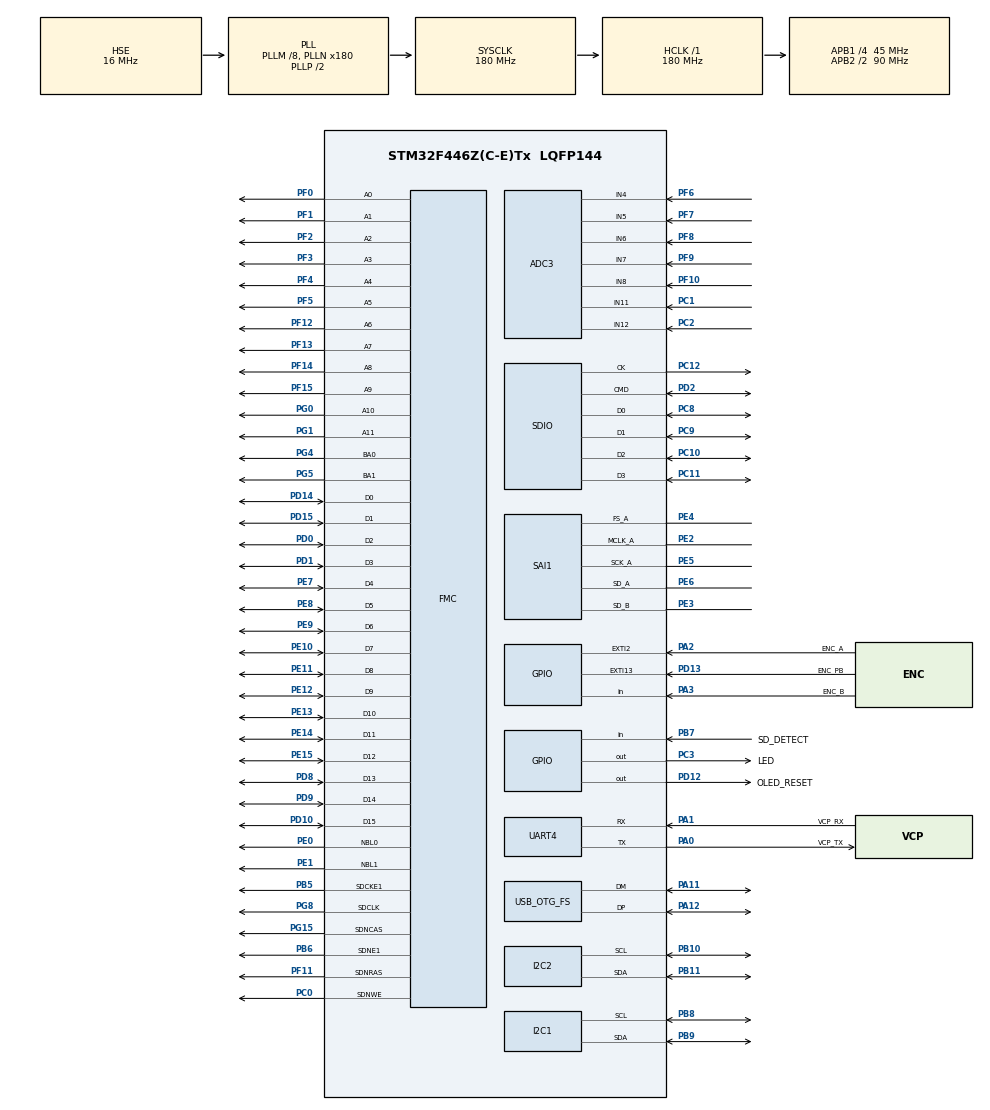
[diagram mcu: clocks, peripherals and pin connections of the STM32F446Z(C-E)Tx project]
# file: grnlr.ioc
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ADC3.Channel-0\#ChannelRegularConversion=ADC_CHANNEL_4
ADC3.NbrOfConversionFlag=1
ADC3.Rank-0\#ChannelRegularConversion=1
ADC3.SamplingTime-0\#ChannelRegularConversion=ADC_SAMPLETIME_3CYCLES
Dma.I2C2_TX.4.Direction=DMA_MEMORY_TO_PERIPH
Dma.I2C2_TX.4.FIFOMode=DMA_FIFOMODE_DISABLE
Dma.I2C2_TX.4.Instance=DMA1_Stream7
Dma.I2C2_TX.4.MemDataAlignment=DMA_MDATAALIGN_BYTE
Dma.I2C2_TX.4.MemInc=DMA_MINC_ENABLE
Dma.I2C2_TX.4.Mode=DMA_NORMAL
Dma.I2C2_TX.4.PeriphDataAlignment=DMA_PDATAALIGN_BYTE
Dma.I2C2_TX.4.PeriphInc=DMA_PINC_DISABLE
Dma.I2C2_TX.4.Priority=DMA_PRIORITY_MEDIUM
Dma.Request0=SAI1_A
Dma.Request1=SAI1_B
Dma.Request2=SDIO_RX
Dma.Request3=SDIO_TX
Dma.Request4=I2C2_TX
Dma.SAI1_A.0.Direction=DMA_MEMORY_TO_PERIPH
Dma.SAI1_A.0.FIFOMode=DMA_FIFOMODE_DISABLE
Dma.SAI1_A.0.Instance=DMA2_Stream1
Dma.SAI1_A.0.MemDataAlignment=DMA_MDATAALIGN_HALFWORD
Dma.SAI1_A.0.MemInc=DMA_MINC_ENABLE
Dma.SAI1_A.0.Mode=DMA_CIRCULAR
Dma.SAI1_A.0.PeriphDataAlignment=DMA_PDATAALIGN_HALFWORD
Dma.SAI1_A.0.PeriphInc=DMA_PINC_DISABLE
Dma.SAI1_A.0.Priority=DMA_PRIORITY_VERY_HIGH
Dma.SAI1_B.1.Direction=DMA_PERIPH_TO_MEMORY
Dma.SAI1_B.1.FIFOMode=DMA_FIFOMODE_DISABLE
Dma.SAI1_B.1.Instance=DMA2_Stream4
Dma.SAI1_B.1.MemDataAlignment=DMA_MDATAALIGN_HALFWORD
Dma.SAI1_B.1.MemInc=DMA_MINC_ENABLE
Dma.SAI1_B.1.Mode=DMA_CIRCULAR
Dma.SAI1_B.1.PeriphDataAlignment=DMA_PDATAALIGN_HALFWORD
Dma.SAI1_B.1.PeriphInc=DMA_PINC_DISABLE
Dma.SAI1_B.1.Priority=DMA_PRIORITY_VERY_HIGH
Dma.SDIO_RX.2.Direction=DMA_PERIPH_TO_MEMORY
Dma.SDIO_RX.2.FIFOMode=DMA_FIFOMODE_ENABLE
Dma.SDIO_RX.2.FIFOThreshold=DMA_FIFO_THRESHOLD_FULL
Dma.SDIO_RX.2.Instance=DMA2_Stream3
Dma.SDIO_RX.2.MemBurst=DMA_MBURST_INC4
Dma.SDIO_RX.2.MemDataAlignment=DMA_MDATAALIGN_WORD
Dma.SDIO_RX.2.MemInc=DMA_MINC_ENABLE
Dma.SDIO_RX.2.Mode=DMA_PFCTRL
Dma.SDIO_RX.2.PeriphBurst=DMA_PBURST_INC4
Dma.SDIO_RX.2.PeriphDataAlignment=DMA_PDATAALIGN_WORD
Dma.SDIO_RX.2.PeriphInc=DMA_PINC_DISABLE
Dma.SDIO_RX.2.Priority=DMA_PRIORITY_HIGH
Dma.SDIO_TX.3.Direction=DMA_MEMORY_TO_PERIPH
Dma.SDIO_TX.3.FIFOMode=DMA_FIFOMODE_ENABLE
Dma.SDIO_TX.3.FIFOThreshold=DMA_FIFO_THRESHOLD_FULL
Dma.SDIO_TX.3.Instance=DMA2_Stream6
Dma.SDIO_TX.3.MemBurst=DMA_MBURST_INC4
Dma.SDIO_TX.3.MemDataAlignment=DMA_MDATAALIGN_WORD
Dma.SDIO_TX.3.MemInc=DMA_MINC_ENABLE
Dma.SDIO_TX.3.Mode=DMA_PFCTRL
Dma.SDIO_TX.3.PeriphBurst=DMA_PBURST_INC4
Dma.SDIO_TX.3.PeriphDataAlignment=DMA_PDATAALIGN_WORD
Dma.SDIO_TX.3.PeriphInc=DMA_PINC_DISABLE
Dma.SDIO_TX.3.Priority=DMA_PRIORITY_HIGH
FATFS.BSP.number=1
FATFS.USE_DMA_CODE_SD=1
FATFS0.BSP.STBoard=false
FATFS0.BSP.api=Unknown
FATFS0.BSP.instance=PB7
FATFS0.BSP.ip=GPIO
FATFS0.BSP.mode=Input
FATFS0.BSP.name=Detect_SDIO
FATFS0.BSP.solution=PB7
FMC.CASLatency1=FMC_SDRAM_CAS_LATENCY_3
FMC.ExitSelfRefreshDelay1=7
FMC.LoadToActiveDelay1=2
FMC.RCDDelay1=2
FMC.RPDelay1=2
FMC.RPDelay2=2
FMC.ReadPipeDelay1=FMC_SDRAM_RPIPE_DELAY_1
FMC.ReadPipeDelay2=FMC_SDRAM_RPIPE_DELAY_1
FMC.RowCycleDelay1=7
FMC.RowCycleDelay2=7
FMC.SDClockPeriod1=FMC_SDRAM_CLOCK_PERIOD_2
FMC.SDClockPeriod2=FMC_SDRAM_CLOCK_PERIOD_2
FMC.SelfRefreshTime1=4
FMC.WriteRecoveryTime1=3
FREERTOS.Tasks01=appTask,8,2048,appTaskStart,Default,NULL,Dynamic,NULL,NULL;SDTask,24,1024,SDTaskStart,Default,NULL,Dynamic,NULL,NULL
FREERTOS.configCHECK_FOR_STACK_OVERFLOW=2
FREERTOS.configGENERATE_RUN_TIME_STATS=1
FREERTOS.configLIBRARY_MAX_SYSCALL_INTERRUPT_PRIORITY=4
FREERTOS.configRECORD_STACK_HIGH_ADDRESS=1
FREERTOS.configUSE_STATS_FORMATTING_FUNCTIONS=1
I2C2.I2C_Mode=I2C_Fast
Mcu.Family=STM32F4
Mcu.Name=STM32F446Z(C-E)Tx
Mcu.Package=LQFP144
NVIC.DMA1_Stream7_IRQn=true\:11\:0\:true\:false\:true\:true\:false\:true\:true
NVIC.DMA2_Stream1_IRQn=true\:10\:0\:true\:false\:true\:true\:false\:true\:true
NVIC.DMA2_Stream3_IRQn=true\:7\:0\:true\:false\:true\:true\:false\:true\:true
NVIC.DMA2_Stream4_IRQn=true\:5\:0\:true\:false\:true\:true\:false\:true\:true
NVIC.DMA2_Stream6_IRQn=true\:8\:0\:true\:false\:true\:true\:false\:true\:true
NVIC.EXTI15_10_IRQn=true\:15\:0\:true\:false\:true\:true\:true\:true\:true
NVIC.EXTI2_IRQn=true\:15\:0\:true\:false\:true\:true\:true\:true\:true
NVIC.FMC_IRQn=true\:15\:0\:true\:false\:true\:true\:true\:true\:true
NVIC.I2C2_ER_IRQn=true\:12\:0\:true\:false\:true\:true\:true\:true\:true
NVIC.I2C2_EV_IRQn=true\:12\:0\:true\:false\:true\:true\:true\:true\:true
NVIC.PriorityGroup=NVIC_PRIORITYGROUP_4
NVIC.SAI1_IRQn=true\:6\:0\:true\:false\:true\:true\:true\:true\:true
NVIC.SDIO_IRQn=true\:9\:0\:true\:false\:true\:true\:true\:true\:true
NVIC.TIM7_IRQn=true\:15\:0\:true\:false\:true\:false\:false\:true\:true
NVIC.TimeBase=TIM7_IRQn
NVIC.TimeBaseIP=TIM7
PA0-WKUP.GPIO_Label=VCP_TX
PA0-WKUP.Mode=Asynchronous
PA0-WKUP.Signal=UART4_TX
PA1.GPIO_Label=VCP_RX
PA1.Mode=Asynchronous
PA1.Signal=UART4_RX
PA11.Mode=Device_Only
PA11.Signal=USB_OTG_FS_DM
PA12.Mode=Device_Only
PA12.Signal=USB_OTG_FS_DP
PA13.Mode=Trace_Asynchronous_SW
PA13.Signal=SYS_JTMS-SWDIO
PA14.Mode=Trace_Asynchronous_SW
PA14.Signal=SYS_JTCK-SWCLK
PA2.GPIO_Label=ENC_A
PA2.GPIO_ModeDefaultEXTI=GPIO_MODE_IT_RISING_FALLING
PA2.Signal=GPXTI2
PA3.GPIO_Label=ENC_B
PA3.Signal=GPIO_Input
PB10.Mode=I2C
PB10.Signal=I2C2_SCL
PB11.Mode=I2C
PB11.Signal=I2C2_SDA
PB3.Mode=Trace_Asynchronous_SW
PB3.Signal=SYS_JTDO-SWO
PB5.Mode=SdramChipSelect2_1
PB5.Signal=FMC_SDCKE1
PB6.Mode=SdramChipSelect2_1
PB6.Signal=FMC_SDNE1
PB7.GPIO_Label=SD_DETECT
PB7.Signal=GPIO_Input
PB8.Mode=I2C
PB8.Signal=I2C1_SCL
PB9.Mode=I2C
PB9.Signal=I2C1_SDA
PC0.Signal=FMC_SDNWE
PC1.Signal=ADCx_IN11
PC10.Mode=SD_4_bits_Wide_bus
PC10.Signal=SDIO_D2
PC11.Mode=SD_4_bits_Wide_bus
PC11.Signal=SDIO_D3
PC12.Mode=SD_4_bits_Wide_bus
PC12.Signal=SDIO_CK
PC14-OSC32_IN.Mode=LSE-External-Oscillator
PC14-OSC32_IN.Signal=RCC_OSC32_IN
PC15-OSC32_OUT.Mode=LSE-External-Oscillator
PC15-OSC32_OUT.Signal=RCC_OSC32_OUT
PC2.Signal=ADCx_IN12
PC3.GPIO_Label=LED
PC3.Signal=GPIO_Output
PC8.Mode=SD_4_bits_Wide_bus
PC8.Signal=SDIO_D0
PC9.Mode=SD_4_bits_Wide_bus
PC9.Signal=SDIO_D1
PD0.Signal=FMC_D2_DA2
PD1.Signal=FMC_D3_DA3
PD10.Signal=FMC_D15_DA15
PD12.GPIO_Label=OLED_RESET
PD12.PinState=GPIO_PIN_SET
PD12.Signal=GPIO_Output
PD13.GPIO_Label=ENC_PB
PD13.GPIO_ModeDefaultEXTI=GPIO_MODE_IT_FALLING
PD13.Signal=GPXTI13
PD14.Signal=FMC_D0_DA0
PD15.Signal=FMC_D1_DA1
PD2.Mode=SD_4_bits_Wide_bus
PD2.Signal=SDIO_CMD
PD8.Signal=FMC_D13_DA13
PD9.Signal=FMC_D14_DA14
PE0.Signal=FMC_NBL0
PE1.Signal=FMC_NBL1
PE10.Signal=FMC_D7_DA7
PE11.Signal=FMC_D8_DA8
PE12.Signal=FMC_D9_DA9
PE13.Signal=FMC_D10_DA10
PE14.Signal=FMC_D11_DA11
PE15.Signal=FMC_D12_DA12
PE2.Mode=SAI_A_MasterWithClock
PE2.Signal=SAI1_MCLK_A
PE3.Mode=SAI_B_SyncSlave
PE3.Signal=SAI1_SD_B
PE4.Mode=SAI_A_MasterWithClock
PE4.Signal=SAI1_FS_A
PE5.Mode=SAI_A_MasterWithClock
PE5.Signal=SAI1_SCK_A
PE6.Mode=SAI_A_MasterWithClock
PE6.Signal=SAI1_SD_A
PE7.Signal=FMC_D4_DA4
PE8.Signal=FMC_D5_DA5
PE9.Signal=FMC_D6_DA6
PF0.Signal=FMC_A0
PF1.Signal=FMC_A1
PF10.Mode=IN8
PF10.Signal=ADC3_IN8
PF11.Signal=FMC_SDNRAS
PF12.Signal=FMC_A6
PF13.Signal=FMC_A7
PF14.Signal=FMC_A8
PF15.Signal=FMC_A9
PF2.Signal=FMC_A2
PF3.Signal=FMC_A3
PF4.Signal=FMC_A4
PF5.Signal=FMC_A5
PF6.Mode=IN4
PF6.Signal=ADC3_IN4
PF7.Mode=IN5
PF7.Signal=ADC3_IN5
PF8.Mode=IN6
PF8.Signal=ADC3_IN6
PF9.Mode=IN7
PF9.Signal=ADC3_IN7
PG0.Signal=FMC_A10
PG1.Signal=FMC_A11
PG15.Signal=FMC_SDNCAS
PG4.Signal=FMC_A14_BA0
PG5.Signal=FMC_A15_BA1
PG8.Signal=FMC_SDCLK
PH0-OSC_IN.Mode=HSE-External-Oscillator
PH0-OSC_IN.Signal=RCC_OSC_IN
PH1-OSC_OUT.Mode=HSE-External-Oscillator
PH1-OSC_OUT.Signal=RCC_OSC_OUT
ProjectManager.HeapSize=0x200
ProjectManager.StackSize=0x800
ProjectManager.TargetToolchain=CMake
RCC.AHBFreq_Value=180000000
RCC.APB1CLKDivider=RCC_HCLK_DIV4
RCC.APB1Freq_Value=45000000
RCC.APB1TimFreq_Value=90000000
RCC.APB2CLKDivider=RCC_HCLK_DIV2
RCC.APB2Freq_Value=90000000
RCC.APB2TimFreq_Value=180000000
RCC.CortexFreq_Value=180000000
RCC.HCLKFreq_Value=180000000
RCC.HSE_VALUE=16000000
RCC.PLLI2SN=123
RCC.PLLI2SQ=10
RCC.PLLM=8
RCC.PLLN=180
RCC.PLLQ=7
RCC.PLLSAIM=8
RCC.PLLSAIN=96
RCC.PLLSAIP=RCC_PLLSAIP_DIV4
RCC.PLLSAIQ=15
RCC.PLLSourceVirtual=RCC_PLLSOURCE_HSE
RCC.SAIACLockSelection=RCC_SAI1CLKSOURCE_PLLI2S
RCC.SYSCLKFreq_VALUE=180000000
RCC.SYSCLKSource=RCC_SYSCLKSOURCE_PLLCLK
RCC.USBCLockSelection=RCC_CLK48CLKSOURCE_PLLSAIP
RCC.USBFreq_Value=48000000
RCC.VCOOutputFreq_Value=360000000
SAI1.AudioFrequency-SAI_A_MasterWithClock=SAI_AUDIO_FREQUENCY_48K
SAI1.ErrorAudioFreq-SAI_A_MasterWithClock=0.09 %
SAI1.InitProtocol-SAI_A_MasterWithClock=Enable
SAI1.InitProtocol-SAI_B_SyncSlave=Enable
SAI1.Instance-SAI_A_MasterWithClock=SAI$Index_Block_A
SAI1.Instance-SAI_B_SyncSlave=SAI$Index_Block_B
SAI1.MClockEnable-SAI_A_MasterWithClock=SAI_MASTERCLOCK_ENABLE
SAI1.RealAudioFreq-SAI_A_MasterWithClock=48.046 KHz
SAI1.VirtualMode-SAI_A_MasterWithClock=VM_MASTER
SAI1.VirtualMode-SAI_B_SyncSlave=VM_SLAVE
SAI1.VirtualProtocol-SAI_A_BASIC=VM_BASIC_PROTOCOL
SAI1.VirtualProtocol-SAI_B_BASIC=VM_BASIC_PROTOCOL
SDIO.ClockDiv=0
SH.ADCx_IN11.0=ADC3_IN11,IN11
SH.ADCx_IN12.0=ADC3_IN12,IN12
SH.FMC_A0.0=FMC_A0,12b-sda1
SH.FMC_A1.0=FMC_A1,12b-sda1
SH.FMC_A10.0=FMC_A10,12b-sda1
SH.FMC_A11.0=FMC_A11,12b-sda1
SH.FMC_A14_BA0.0=FMC_BA0,FourSdramBanks1
SH.FMC_A15_BA1.0=FMC_BA1,FourSdramBanks1
SH.FMC_A2.0=FMC_A2,12b-sda1
SH.FMC_A3.0=FMC_A3,12b-sda1
SH.FMC_A4.0=FMC_A4,12b-sda1
SH.FMC_A5.0=FMC_A5,12b-sda1
SH.FMC_A6.0=FMC_A6,12b-sda1
SH.FMC_A7.0=FMC_A7,12b-sda1
SH.FMC_A8.0=FMC_A8,12b-sda1
SH.FMC_A9.0=FMC_A9,12b-sda1
SH.FMC_D0_DA0.0=FMC_D0,sd-16b-d1
SH.FMC_D10_DA10.0=FMC_D10,sd-16b-d1
SH.FMC_D11_DA11.0=FMC_D11,sd-16b-d1
SH.FMC_D12_DA12.0=FMC_D12,sd-16b-d1
SH.FMC_D13_DA13.0=FMC_D13,sd-16b-d1
SH.FMC_D14_DA14.0=FMC_D14,sd-16b-d1
SH.FMC_D15_DA15.0=FMC_D15,sd-16b-d1
SH.FMC_D1_DA1.0=FMC_D1,sd-16b-d1
SH.FMC_D2_DA2.0=FMC_D2,sd-16b-d1
SH.FMC_D3_DA3.0=FMC_D3,sd-16b-d1
SH.FMC_D4_DA4.0=FMC_D4,sd-16b-d1
SH.FMC_D5_DA5.0=FMC_D5,sd-16b-d1
SH.FMC_D6_DA6.0=FMC_D6,sd-16b-d1
SH.FMC_D7_DA7.0=FMC_D7,sd-16b-d1
SH.FMC_D8_DA8.0=FMC_D8,sd-16b-d1
SH.FMC_D9_DA9.0=FMC_D9,sd-16b-d1
SH.FMC_NBL0.0=FMC_NBL0,Sd2ByteEnable1
SH.FMC_NBL1.0=FMC_NBL1,Sd2ByteEnable1
SH.FMC_SDCLK.0=FMC_SDCLK,12b-sda1
SH.FMC_SDNCAS.0=FMC_SDNCAS,12b-sda1
SH.FMC_SDNRAS.0=FMC_SDNRAS,12b-sda1
SH.FMC_SDNWE.0=FMC_SDNWE,12b-sda1
TIM2.Prescaler=900-1
TIM6.Prescaler=120-1
UART4.VirtualMode=Asynchronous
USB_OTG_FS.VirtualMode=Device_Only
VP_FATFS_VS_SDIO.Mode=SDIO
VP_FREERTOS_VS_CMSIS_V2.Mode=CMSIS_V2
VP_SAI1_VP_$IpInstance_SAIA_SAI_BASIC.Mode=SAI_A_BASIC
VP_SAI1_VP_$IpInstance_SAIB_SAI_BASIC.Mode=SAI_B_BASIC
VP_SYS_VS_tim7.Mode=TIM7
VP_TIM2_VS_ClockSourceINT.Mode=Internal
VP_TIM6_VS_ClockSourceINT.Mode=Enable_Timer
board=custom

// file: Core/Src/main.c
/* USER CODE BEGIN Header */
/**
 ******************************************************************************
 * @file           : main.c
 * @brief          : Main program body
 ******************************************************************************
 * @attention
 *
 * Copyright (c) 2025 STMicroelectronics.
 * All rights reserved.
 *
 * This software is licensed under terms that can be found in the LICENSE file
 * in the root directory of this software component.
 * If no LICENSE file comes with this software, it is provided AS-IS.
 *
 ******************************************************************************
 */
/* USER CODE END Header */
#include "main.h"
#include "cmsis_os.h"
#include "adc.h"
#include "dma.h"
#include "fatfs.h"
#include "i2c.h"
#include "sai.h"
#include "sdio.h"
#include "tim.h"
#include "usart.h"
#include "usb_otg.h"
#include "gpio.h"
#include "fmc.h"

/* USER CODE BEGIN Includes */
#include <stdio.h>

#include "app.h"
#include "coder.h"
#include "ssd1306.h"
/* USER CODE END Includes */

/* USER CODE BEGIN PV */
#define __sdram __attribute__((section(".sdram_data")))

// #define AUDIO_BUFFER_LENGTH 2097152	// 8MB
// __sdram uint32_t audio_buffer[AUDIO_BUFFER_LENGTH];
/* USER CODE END PV */

void SystemClock_Config(void);
void PeriphCommonClock_Config(void);
void MX_FREERTOS_Init(void);

/* USER CODE BEGIN 0 */

void HAL_GPIO_EXTI_Callback(uint16_t GPIO_Pin)
{
	switch(GPIO_Pin)
	{
		case ENC_PB_Pin:
			coder_pb_pressed_cb(&h_coder);
			break;
		case ENC_A_Pin:
			if (HAL_GPIO_ReadPin(ENC_A_GPIO_Port, ENC_A_Pin) != HAL_GPIO_ReadPin(ENC_B_GPIO_Port, ENC_B_Pin))
			{
				coder_increment_cb(&h_coder, 1);
			}
			if (HAL_GPIO_ReadPin(ENC_A_GPIO_Port, ENC_A_Pin) == HAL_GPIO_ReadPin(ENC_B_GPIO_Port, ENC_B_Pin))
			{
				coder_increment_cb(&h_coder, -1);
			}

			break;
		case ENC_B_Pin:
			break;
		default:
			break;
	}
}

void HAL_SAI_TxHalfCpltCallback(SAI_HandleTypeDef *hsai)
{
	if (SAI1_Block_A == hsai->Instance)
	{
		// Nothing for now
	}
}

void HAL_SAI_TxCpltCallback(SAI_HandleTypeDef *hsai)
{
	if (SAI1_Block_A == hsai->Instance)
	{
		// Nothing for now
	}
}

void HAL_SAI_RxHalfCpltCallback(SAI_HandleTypeDef *hsai)
{
	if (SAI1_Block_B == hsai->Instance)
	{
		h_stats.period = __HAL_TIM_GET_COUNTER(&htim6);
		__HAL_TIM_SET_COUNTER(&htim6, 0);

		//process first half of h_sgtl5000 buffer
		app_process_audio(
				h_sgtl5000.sai_rx_buffer,
				h_sgtl5000.sai_tx_buffer,
				AUDIO_BUFFER_LENGTH * AUDIO_NUM_CHANNELS
				);

		h_stats.duration = __HAL_TIM_GET_COUNTER(&htim6);
	}
}

void HAL_SAI_RxCpltCallback(SAI_HandleTypeDef *hsai)
{
	if (SAI1_Block_B == hsai->Instance)
	{
		h_stats.period = __HAL_TIM_GET_COUNTER(&htim6);
		__HAL_TIM_SET_COUNTER(&htim6, 0);

		//process second half of h_sgtl5000 buffer
		app_process_audio(
				&h_sgtl5000.sai_rx_buffer[AUDIO_BUFFER_LENGTH * AUDIO_NUM_CHANNELS],
				&h_sgtl5000.sai_tx_buffer[AUDIO_BUFFER_LENGTH * AUDIO_NUM_CHANNELS],
				AUDIO_BUFFER_LENGTH * AUDIO_NUM_CHANNELS
				);

		h_stats.duration = __HAL_TIM_GET_COUNTER(&htim6);
	}
}

void HAL_I2C_MemTxCpltCallback(I2C_HandleTypeDef *hi2c)
{
	if (I2C2 == hi2c->Instance)
	{
		ssd1306_i2c_mem_write_cb();
	}
}

#define SDRAM_MODEREG_BURST_LENGTH_1             ((uint16_t)0x0000)
#define SDRAM_MODEREG_BURST_LENGTH_2             ((uint16_t)0x0001)
#define SDRAM_MODEREG_BURST_LENGTH_4             ((uint16_t)0x0002)
#define SDRAM_MODEREG_BURST_LENGTH_8             ((uint16_t)0x0004)
#define SDRAM_MODEREG_BURST_TYPE_SEQUENTIAL      ((uint16_t)0x0000)
#define SDRAM_MODEREG_BURST_TYPE_INTERLEAVED     ((uint16_t)0x0008)
#define SDRAM_MODEREG_CAS_LATENCY_2              ((uint16_t)0x0020)
#define SDRAM_MODEREG_CAS_LATENCY_3              ((uint16_t)0x0030)
#define SDRAM_MODEREG_OPERATING_MODE_STANDARD    ((uint16_t)0x0000)
#define SDRAM_MODEREG_WRITEBURST_MODE_PROGRAMMED ((uint16_t)0x0000)
#define SDRAM_MODEREG_WRITEBURST_MODE_SINGLE     ((uint16_t)0x0200)

static HAL_StatusTypeDef SDRAM_Initialization_Sequence(SDRAM_HandleTypeDef *hsdram)
{
	HAL_StatusTypeDef ret;
	FMC_SDRAM_CommandTypeDef command;
	__IO uint32_t tmpmrd =0;
	/* Step 3:  Configure a clock configuration enable command */
	command.CommandMode 			 = FMC_SDRAM_CMD_CLK_ENABLE;
	command.CommandTarget 		 = FMC_SDRAM_CMD_TARGET_BANK2;
	command.AutoRefreshNumber 	 = 1;
	command.ModeRegisterDefinition = 0;

	/* Send the command */
	ret = HAL_SDRAM_SendCommand(hsdram, &command, 0x1000);
	if (ret != HAL_OK)
	{
		return ret;
	}

	/* Step 4: Insert 100 ms delay */
	HAL_Delay(100);

	/* Step 5: Configure a PALL (precharge all) command */
	command.CommandMode 			 = FMC_SDRAM_CMD_PALL;
	command.CommandTarget 	     = FMC_SDRAM_CMD_TARGET_BANK2;
	command.AutoRefreshNumber 	 = 1;
	command.ModeRegisterDefinition = 0;

	/* Send the command */
	ret = HAL_SDRAM_SendCommand(hsdram, &command, 0x1000);
	if (ret != HAL_OK)
	{
		return ret;
	}

	/* Step 6 : Configure a Auto-Refresh command */
	command.CommandMode 			 = FMC_SDRAM_CMD_AUTOREFRESH_MODE;
	command.CommandTarget 		 = FMC_SDRAM_CMD_TARGET_BANK2;
	command.AutoRefreshNumber 	 = 4;
	command.ModeRegisterDefinition = 0;

	/* Send the command */
	ret = HAL_SDRAM_SendCommand(hsdram, &command, 0x1000);
	if (ret != HAL_OK)
	{
		return ret;
	}

	/* Step 7: Program the external memory mode register */
	tmpmrd = (uint32_t)SDRAM_MODEREG_BURST_LENGTH_2          |
		SDRAM_MODEREG_BURST_TYPE_SEQUENTIAL   |
		SDRAM_MODEREG_CAS_LATENCY_3           |
		SDRAM_MODEREG_OPERATING_MODE_STANDARD |
		SDRAM_MODEREG_WRITEBURST_MODE_SINGLE;

	command.CommandMode = FMC_SDRAM_CMD_LOAD_MODE;
	command.CommandTarget 		 = FMC_SDRAM_CMD_TARGET_BANK2;
	command.AutoRefreshNumber 	 = 1;
	command.ModeRegisterDefinition = tmpmrd;

	/* Send the command */
	ret = HAL_SDRAM_SendCommand(hsdram, &command, 0x1000);
	if (ret != HAL_OK)
	{
		return ret;
	}

	/* Step 8: Set the refresh rate counter */
	/* (15.62 us x Freq) - 20 */
	/* (15.62 * 180) - 20 = 2792 */
	/* Set the device refresh counter */
	return HAL_SDRAM_ProgramRefreshRate(hsdram, 2792);
	// was 0x056A for 90MHz
}

uint32_t sdram_test(uint32_t* buffer, uint32_t size)
{
	uint32_t fail = 0;
	uint32_t tick = HAL_GetTick();
	for (uint32_t i = 0 ; i < size ; i++)
	{
		buffer[i] = i;
	}
	uint32_t new_tick = HAL_GetTick();
	printf("8MB written in %lu ms\r\n", new_tick - tick);
	tick = HAL_GetTick();
	for (uint32_t i = 0 ; i < size ; i++)
	{
		if (buffer[i] != i)
		{
			fail++;
		}
	}
	new_tick = HAL_GetTick();
	printf("8MB read in %lu ms\r\n", new_tick - tick);
	return fail;
}
/* USER CODE END 0 */

int main(void)
{

  /* MCU Configuration--------------------------------------------------------*/

  /* Reset of all peripherals, Initializes the Flash interface and the Systick. */
  HAL_Init();

  /* Configure the system clock */
  SystemClock_Config();

  /* Configure the peripherals common clocks */
  PeriphCommonClock_Config();

  /* Initialize all configured peripherals */
  MX_GPIO_Init();
  MX_DMA_Init();
  MX_FMC_Init();
  MX_ADC3_Init();
  MX_I2C1_Init();
  MX_SAI1_Init();
  MX_SDIO_SD_Init();
  MX_UART4_Init();
  MX_USB_OTG_FS_PCD_Init();
  MX_FATFS_Init();
  MX_I2C2_Init();
  MX_TIM6_Init();
  MX_TIM2_Init();
  /* USER CODE BEGIN 2 */
	if (SDRAM_Initialization_Sequence(&hsdram1) != HAL_OK)
	{
		printf("failed to initialize SDRAM\r\n");
	}

	// app_init();

	// app_process();
  /* USER CODE END 2 */

  /* Init scheduler */
  osKernelInitialize();  /* Call init function for freertos objects (in cmsis_os2.c) */
  MX_FREERTOS_Init();

  /* Start scheduler */
  osKernelStart();

  /* We should never get here as control is now taken by the scheduler */

  /* Infinite loop */
	while (1)
	{

	}
}

void SystemClock_Config(void)
{
  RCC_OscInitTypeDef RCC_OscInitStruct = {0};
  RCC_ClkInitTypeDef RCC_ClkInitStruct = {0};

  /** Configure the main internal regulator output voltage
  */
  __HAL_RCC_PWR_CLK_ENABLE();
  __HAL_PWR_VOLTAGESCALING_CONFIG(PWR_REGULATOR_VOLTAGE_SCALE1);

  /** Initializes the RCC Oscillators according to the specified parameters
  * in the RCC_OscInitTypeDef structure.
  */
  RCC_OscInitStruct.OscillatorType = RCC_OSCILLATORTYPE_HSE;
  RCC_OscInitStruct.HSEState = RCC_HSE_ON;
  RCC_OscInitStruct.PLL.PLLState = RCC_PLL_ON;
  RCC_OscInitStruct.PLL.PLLSource = RCC_PLLSOURCE_HSE;
  RCC_OscInitStruct.PLL.PLLM = 8;
  RCC_OscInitStruct.PLL.PLLN = 180;
  RCC_OscInitStruct.PLL.PLLP = RCC_PLLP_DIV2;
  RCC_OscInitStruct.PLL.PLLQ = 7;
  RCC_OscInitStruct.PLL.PLLR = 2;
  if (HAL_RCC_OscConfig(&RCC_OscInitStruct) != HAL_OK)
  {
    Error_Handler();
  }

  /** Activate the Over-Drive mode
  */
  if (HAL_PWREx_EnableOverDrive() != HAL_OK)
  {
    Error_Handler();
  }

  /** Initializes the CPU, AHB and APB buses clocks
  */
  RCC_ClkInitStruct.ClockType = RCC_CLOCKTYPE_HCLK|RCC_CLOCKTYPE_SYSCLK
                              |RCC_CLOCKTYPE_PCLK1|RCC_CLOCKTYPE_PCLK2;
  RCC_ClkInitStruct.SYSCLKSource = RCC_SYSCLKSOURCE_PLLCLK;
  RCC_ClkInitStruct.AHBCLKDivider = RCC_SYSCLK_DIV1;
  RCC_ClkInitStruct.APB1CLKDivider = RCC_HCLK_DIV4;
  RCC_ClkInitStruct.APB2CLKDivider = RCC_HCLK_DIV2;

  if (HAL_RCC_ClockConfig(&RCC_ClkInitStruct, FLASH_LATENCY_5) != HAL_OK)
  {
    Error_Handler();
  }
}

void PeriphCommonClock_Config(void)
{
  RCC_PeriphCLKInitTypeDef PeriphClkInitStruct = {0};

  /** Initializes the peripherals clock
  */
  PeriphClkInitStruct.PeriphClockSelection = RCC_PERIPHCLK_SAI1|RCC_PERIPHCLK_SDIO
                              |RCC_PERIPHCLK_CLK48;
  PeriphClkInitStruct.PLLI2S.PLLI2SN = 123;
  PeriphClkInitStruct.PLLI2S.PLLI2SP = RCC_PLLI2SP_DIV2;
  PeriphClkInitStruct.PLLI2S.PLLI2SM = 16;
  PeriphClkInitStruct.PLLI2S.PLLI2SR = 2;
  PeriphClkInitStruct.PLLI2S.PLLI2SQ = 10;
  PeriphClkInitStruct.PLLSAI.PLLSAIM = 8;
  PeriphClkInitStruct.PLLSAI.PLLSAIN = 96;
  PeriphClkInitStruct.PLLSAI.PLLSAIQ = 15;
  PeriphClkInitStruct.PLLSAI.PLLSAIP = RCC_PLLSAIP_DIV4;
  PeriphClkInitStruct.PLLI2SDivQ = 1;
  PeriphClkInitStruct.PLLSAIDivQ = 1;
  PeriphClkInitStruct.Clk48ClockSelection = RCC_CLK48CLKSOURCE_PLLSAIP;
  PeriphClkInitStruct.SdioClockSelection = RCC_SDIOCLKSOURCE_CLK48;
  PeriphClkInitStruct.Sai1ClockSelection = RCC_SAI1CLKSOURCE_PLLI2S;
  if (HAL_RCCEx_PeriphCLKConfig(&PeriphClkInitStruct) != HAL_OK)
  {
    Error_Handler();
  }
}

void HAL_TIM_PeriodElapsedCallback(TIM_HandleTypeDef *htim)
{
  if (htim->Instance == TIM7)
  {
    HAL_IncTick();
  }
}

void Error_Handler(void)
{
	__disable_irq();
	while (1)
	{
	}
}

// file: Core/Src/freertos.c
/* USER CODE BEGIN Header */
/**
 ******************************************************************************
 * File Name          : freertos.c
 * Description        : Code for freertos applications
 ******************************************************************************
 * @attention
 *
 * Copyright (c) 2025 STMicroelectronics.
 * All rights reserved.
 *
 * This software is licensed under terms that can be found in the LICENSE file
 * in the root directory of this software component.
 * If no LICENSE file comes with this software, it is provided AS-IS.
 *
 ******************************************************************************
 */
/* USER CODE END Header */

#include "FreeRTOS.h"
#include "task.h"
#include "main.h"
#include "cmsis_os.h"

/* USER CODE BEGIN Includes */
#include "app.h"
#include "playback.h"
/* USER CODE END Includes */

/* Definitions for appTask */
osThreadId_t appTaskHandle;
const osThreadAttr_t appTask_attributes = {
  .name = "appTask",
  .stack_size = 2048 * 4,
  .priority = (osPriority_t) osPriorityLow,
};
/* Definitions for SDTask */
osThreadId_t SDTaskHandle;
const osThreadAttr_t SDTask_attributes = {
  .name = "SDTask",
  .stack_size = 1024 * 4,
  .priority = (osPriority_t) osPriorityNormal,
};

void appTaskStart(void *argument);
void SDTaskStart(void *argument);

void MX_FREERTOS_Init(void); /* (MISRA C 2004 rule 8.1) */

/* Hook prototypes */
void configureTimerForRunTimeStats(void);
unsigned long getRunTimeCounterValue(void);
void vApplicationStackOverflowHook(xTaskHandle xTask, signed char *pcTaskName);

/* USER CODE BEGIN 1 */
/* Functions needed when configGENERATE_RUN_TIME_STATS is on */
void configureTimerForRunTimeStats(void)
{
	HAL_TIM_Base_Start(&htim2);
}

unsigned long getRunTimeCounterValue(void)
{
	return __HAL_TIM_GET_COUNTER(&htim2);
}
/* USER CODE END 1 */

/* USER CODE BEGIN 4 */
void vApplicationStackOverflowHook(xTaskHandle xTask, signed char *pcTaskName)
{
  __disable_irq();
  while(1);
}
/* USER CODE END 4 */

void MX_FREERTOS_Init(void) {

  /* Create the thread(s) */
  /* creation of appTask */
  appTaskHandle = osThreadNew(appTaskStart, NULL, &appTask_attributes);

  /* creation of SDTask */
  SDTaskHandle = osThreadNew(SDTaskStart, NULL, &SDTask_attributes);

}

void appTaskStart(void *argument)
{
  /* USER CODE BEGIN appTaskStart */

	app_init();

	app_process();

	/* Infinite loop */
	for(;;)
	{
		osDelay(1);
	}
  /* USER CODE END appTaskStart */
}

void SDTaskStart(void *argument)
{
  /* USER CODE BEGIN SDTaskStart */

	playback_init(&h_playback);

	/* Infinite loop */
	for(;;)
	{
		playback_process(&h_playback);
	}
  /* USER CODE END SDTaskStart */
}
